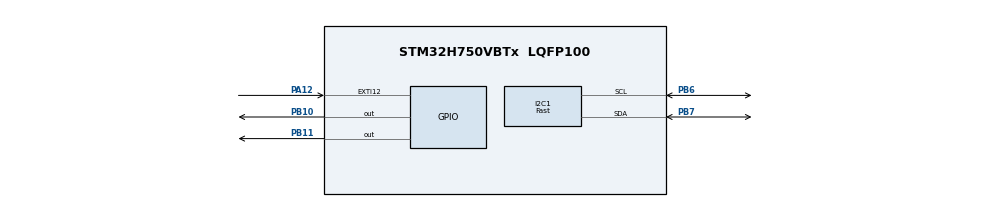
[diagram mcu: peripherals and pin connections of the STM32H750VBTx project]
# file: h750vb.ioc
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I2C1.I2C_Speed_Mode=I2C_Fast
I2C1.Timing=0x00401959
Mcu.Family=STM32H7
Mcu.Name=STM32H750VBTx
Mcu.Package=LQFP100
NVIC.EXTI15_10_IRQn=true\:0\:0\:false\:false\:true\:true\:true\:true
NVIC.PriorityGroup=NVIC_PRIORITYGROUP_4
NVIC.TIM3_IRQn=true\:0\:0\:false\:false\:true\:true\:true\:true
PA12.GPIO_ModeDefaultEXTI=GPIO_MODE_IT_RISING
PA12.GPIO_PuPd=GPIO_PULLDOWN
PA12.Signal=GPXTI12
PA2.GPIO_ModeDefaultPP=GPIO_MODE_AF_PP
PA2.Signal=USART2_TX
PB10.GPIO_ModeDefaultOutputPP=GPIO_MODE_OUTPUT_OD
PB10.GPIO_PuPd=GPIO_NOPULL
PB10.GPIO_Speed=GPIO_SPEED_FREQ_MEDIUM
PB10.Signal=GPIO_Output
PB11.GPIO_ModeDefaultOutputPP=GPIO_MODE_OUTPUT_OD
PB11.GPIO_PuPd=GPIO_NOPULL
PB11.Signal=GPIO_Output
PB6.Mode=I2C
PB6.Signal=I2C1_SCL
PB7.Mode=I2C
PB7.Signal=I2C1_SDA
PH0-OSC_IN\ (PH0).Mode=HSE-External-Oscillator
PH0-OSC_IN\ (PH0).Signal=RCC_OSC_IN
PH1-OSC_OUT\ (PH1).Mode=HSE-External-Oscillator
PH1-OSC_OUT\ (PH1).Signal=RCC_OSC_OUT
ProjectManager.HeapSize=0x200
ProjectManager.StackSize=0x400
ProjectManager.TargetToolchain=STM32CubeIDE
RCC.ADCFreq_Value=50390625
RCC.APB1Freq_Value=50000000
RCC.APB2Freq_Value=100000000
RCC.APB3Freq_Value=100000000
RCC.APB4Freq_Value=100000000
RCC.CortexFreq_Value=200000000
RCC.D1PPRE=RCC_APB3_DIV2
RCC.D2PPRE1=RCC_APB1_DIV4
RCC.D2PPRE2=RCC_APB2_DIV2
RCC.D3PPRE=RCC_APB4_DIV2
RCC.DIVM1=2
RCC.DIVN1=32
RCC.EnbaleCSS=true
RCC.HCLKFreq_Value=200000000
RCC.HSE_VALUE=25000000
RCC.PLL2FRACN=0
RCC.PLL3FRACN=0
RCC.PLLFRACN=0
RCC.PLLSourceVirtual=RCC_PLLSOURCE_HSE
RCC.SYSCLKFreq_VALUE=200000000
RCC.SYSCLKSource=RCC_SYSCLKSOURCE_PLLCLK
RCC.USBFreq_Value=200000000
TIM3.AutoReloadPreload=TIM_AUTORELOAD_PRELOAD_ENABLE
TIM3.Period=1999
TIM3.Prescaler=1999
VP_TIM3_VS_ClockSourceINT.Mode=Internal
board=custom

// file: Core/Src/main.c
/* USER CODE BEGIN Header */
/**
  ******************************************************************************
  * @file           : main.c
  * @brief          : Main program body
  ******************************************************************************
  * @attention
  *
  * Copyright (c) 2023 STMicroelectronics.
  * All rights reserved.
  *
  * This software is licensed under terms that can be found in the LICENSE file
  * in the root directory of this software component.
  * If no LICENSE file comes with this software, it is provided AS-IS.
  *
  ******************************************************************************
  */
/* USER CODE END Header */
#include "main.h"
#include "i2c.h"
#include "tim.h"
#include "gpio.h"

/* USER CODE BEGIN Includes */
#include "string.h"
#include "OLED.h"
/* USER CODE END Includes */

/* USER CODE BEGIN PV */
//	extern unsigned char i_BusData[36];
/* USER CODE END PV */

void SystemClock_Config(void);

/* USER CODE BEGIN 0 */
//void HAL_TIM_PeriodElapsedCallback(TIM_HandleTypeDef *htim)
//{
//	Kalman_Loop(0.001);
//	char angles[20];
//	sprintf(angles, "%lf", yaw);
//	HAL_UART_Transmit(&huart2, angles, 20, 10);
//}
/* USER CODE END 0 */

int main(void)
{

  /* MCU Configuration--------------------------------------------------------*/

  /* Reset of all peripherals, Initializes the Flash interface and the Systick. */
  HAL_Init();

  /* Configure the system clock */
  SystemClock_Config();

  /* Initialize all configured peripherals */
  MX_GPIO_Init();
  MX_I2C1_Init();
  MX_TIM3_Init();
  /* USER CODE BEGIN 2 */

//  HAL_TIM_Base_Start_IT(&htim3);
//  HMC5883L_INIT(&hi2c1);
//  __HAL_DMA_DISABLE_IT(&hdma_usart2_rx, DMA_IT_HT);
//  HAL_UART_Receive_DMA(&huart2, i_BusData, 32);
//  __HAL_DMA_DISABLE_IT(&hdma_usart2_rx, DMA_IT_HT);

//  BMP085_InitDataTypdef BMP_InitData = BMP085_GetInitData(&hi2c1);
//  unsigned char al[20] = "\0";
//  OLED_Init();
//  float BMP180_GetAlt (int oss);
  /* USER CODE END 2 */

  /* Infinite loop */
  /* USER CODE BEGIN WHILE */
  while (1)
  {
//	  BMP085_InitDataTypdef Init_Data = BMP085_GetInitData(&hi2c1);
//	  BMP085_GetData(&hi2c1, &Init_Data, 1);
//	  BMP180_GetAlt(1);
//	for(char i = 0; i < 70; i++)
//	{
//		OLED_NewFrame();
//		OLED_PrintString(128 - 2 * i, 40, "HHH", &font16x16, OLED_COLOR_NORMAL);
//		OLED_ShowFrame();
//	}

//	HAL_Delay(1000);

	  //  OLED_DrawCircle(5, 6, 5, 1);

//	  unsigned char xx[20];
//	  Kalman_Loop(0.001);
//	  sprintf(xx, "%lf", yaw);
//	  HAL_UART_Transmit(&huart2, xx, 20, 100);
//	  BMP085_DataTypdef BMP085_Data = BMP085_GetData(&hi2c1, &BMP_InitData, 1);
//	  snprintf(al, 20, "%lf\n", BMP085_GetAltitude(BMP085_Data.Pres));
//	  HAL_UART_Transmit(&huart2, al, 20, 100);
//		unsigned char UPMode = BMP_COVERT_PRES;
//		HAL_I2C_Mem_Write(&hi2c1, BMP085_ADDR, CONTROL_REG_ADDR, 1, &UPMode, 1, 10);//切换为压强读取，标准模式
//		HAL_Delay(15);
//	  HAL_I2C_Mem_Read(&hi2c1, BMP085_ADDR, BMP_TEMP_PRES_DATA_REG, 1, al, 3, 10);
//	  HAL_UART_Transmit(&huart2, al, 3, 100);
//	  HAL_Delay(100);
    /* USER CODE END WHILE */

  }
}

void SystemClock_Config(void)
{
  RCC_OscInitTypeDef RCC_OscInitStruct = {0};
  RCC_ClkInitTypeDef RCC_ClkInitStruct = {0};

  /** Supply configuration update enable
  */
  HAL_PWREx_ConfigSupply(PWR_LDO_SUPPLY);

  /** Configure the main internal regulator output voltage
  */
  __HAL_PWR_VOLTAGESCALING_CONFIG(PWR_REGULATOR_VOLTAGE_SCALE3);

  while(!__HAL_PWR_GET_FLAG(PWR_FLAG_VOSRDY)) {}

  /** Initializes the RCC Oscillators according to the specified parameters
  * in the RCC_OscInitTypeDef structure.
  */
  RCC_OscInitStruct.OscillatorType = RCC_OSCILLATORTYPE_HSE;
  RCC_OscInitStruct.HSEState = RCC_HSE_ON;
  RCC_OscInitStruct.PLL.PLLState = RCC_PLL_ON;
  RCC_OscInitStruct.PLL.PLLSource = RCC_PLLSOURCE_HSE;
  RCC_OscInitStruct.PLL.PLLM = 2;
  RCC_OscInitStruct.PLL.PLLN = 32;
  RCC_OscInitStruct.PLL.PLLP = 2;
  RCC_OscInitStruct.PLL.PLLQ = 2;
  RCC_OscInitStruct.PLL.PLLR = 2;
  RCC_OscInitStruct.PLL.PLLRGE = RCC_PLL1VCIRANGE_3;
  RCC_OscInitStruct.PLL.PLLVCOSEL = RCC_PLL1VCOWIDE;
  RCC_OscInitStruct.PLL.PLLFRACN = 0;
  if (HAL_RCC_OscConfig(&RCC_OscInitStruct) != HAL_OK)
  {
    Error_Handler();
  }

  /** Initializes the CPU, AHB and APB buses clocks
  */
  RCC_ClkInitStruct.ClockType = RCC_CLOCKTYPE_HCLK|RCC_CLOCKTYPE_SYSCLK
                              |RCC_CLOCKTYPE_PCLK1|RCC_CLOCKTYPE_PCLK2
                              |RCC_CLOCKTYPE_D3PCLK1|RCC_CLOCKTYPE_D1PCLK1;
  RCC_ClkInitStruct.SYSCLKSource = RCC_SYSCLKSOURCE_PLLCLK;
  RCC_ClkInitStruct.SYSCLKDivider = RCC_SYSCLK_DIV1;
  RCC_ClkInitStruct.AHBCLKDivider = RCC_HCLK_DIV1;
  RCC_ClkInitStruct.APB3CLKDivider = RCC_APB3_DIV2;
  RCC_ClkInitStruct.APB1CLKDivider = RCC_APB1_DIV4;
  RCC_ClkInitStruct.APB2CLKDivider = RCC_APB2_DIV2;
  RCC_ClkInitStruct.APB4CLKDivider = RCC_APB4_DIV2;

  if (HAL_RCC_ClockConfig(&RCC_ClkInitStruct, FLASH_LATENCY_4) != HAL_OK)
  {
    Error_Handler();
  }

  /** Enables the Clock Security System
  */
  HAL_RCC_EnableCSS();
}

void Error_Handler(void)
{
  __disable_irq();
  while (1)
  {
  }
}
